# MAX32600 register map
File version: 1.0
Registers are 32-bit, read-write, reset 0x0 unless marked. A register's access mark holds for its fields unless they carry their own. Offsets are from the block's base; [hi:lo] are bit positions; {n}, {i} and the like mark numbered series.

## ADCCFG — ADC
Base 0x40054038
0x00 CTRL1 — ADC Control Register 1
  [18:16] scan_cnt — Channel Scan Count
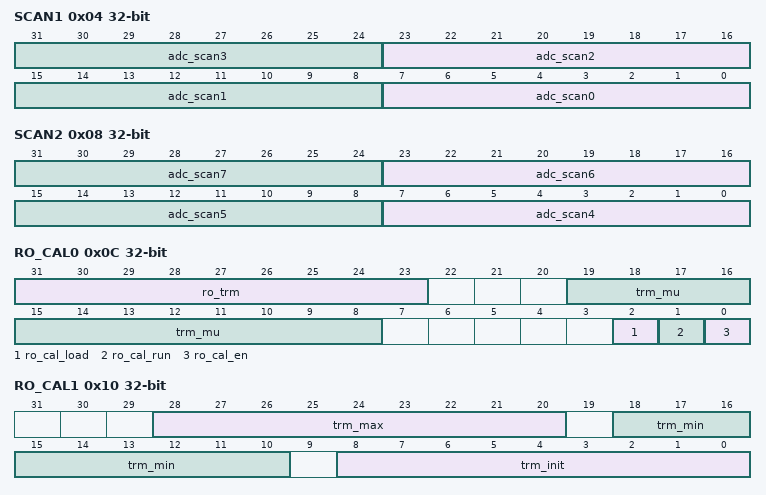
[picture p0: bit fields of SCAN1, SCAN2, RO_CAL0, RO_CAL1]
0x04 SCAN1 — ADC Auto-Scan Settings 1
  [8n+7:8n] adc_scan{n} (n=0..3) — ADC Scan Configuration - Channel {n}
0x08 SCAN2 — ADC Auto-Scan Settings 2
  [8n-25:8n-32] adc_scan{n} (n=4..7) — ADC Scan Configuration - Channel {n}
0x0C RO_CAL0 — ADC Relaxation Oscillator Calibration 0
  [31:23] ro_trm ro — Auto Calibration Loop Register Readback
  [19:8] trm_mu — Auto Calibration Loop Gain
  [2] ro_cal_load — Load Initial RO Calibration Trim
  [1] ro_cal_run — Enable Closed Loop Control
  [0] ro_cal_en — Relaxation Oscillator Auto-Calibration Enable
0x10 RO_CAL1 — ADC Relaxation Oscillator Calibration 1
  [28:20] trm_max — Trim Upper Limit
  [18:10] trm_min — Trim Lower Limit
  [8:0] trm_init — Initial Setting for RO Trim Calibration

## PMU0 — Peripheral Management Unit
Base 0x40070000
Same registers: PMU1 0x40070020, PMU2 0x40070040, PMU3 0x40070060, PMU4 0x40070080, PMU5 0x400700A0
0x00 DSCADR — Starting Descriptor Address
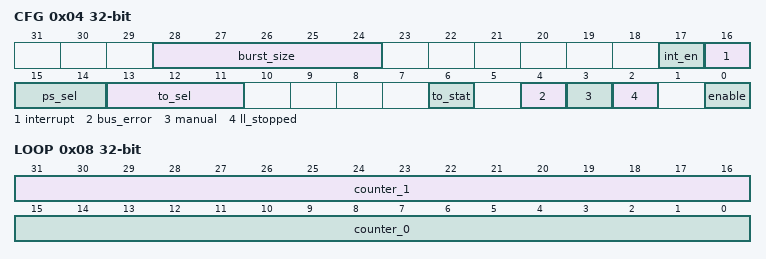
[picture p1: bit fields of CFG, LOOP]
0x04 CFG — Channel Configuration
  [28:24] burst_size — DMA Maximum Burst Size
  [17] int_en — PMU Channel Interrupt Enable
  [16] interrupt write-1-clears — Descriptor Interrupt Flag
  [15:14] ps_sel — Time Out Interval Prescale Select
  [13:11] to_sel — Time Out Interval Select
  [6] to_stat write-1-clears — AHB Bus Timeout Interrupt Flag
  [4] bus_error write-1-clears — AHB Bus Error Interrupt Flag
  [3] manual — Manual Mode Enable
  [2] ll_stopped — Linked List Engine Status
  [0] enable — PMU Channel Enable
0x08 LOOP — Channel Loop Counters
  [31:16] counter_1 — CH1 Loop Counter 0
  [15:0] counter_0 — CH1 Loop Counter 1
0x0C OP — Current Descriptor DWORD 0 (OP)
{0xC+4i} DSC{i} (i=1..4) — Current Descriptor DWORD {i}

## ICC — Instruction Cache
Base 0x40080000
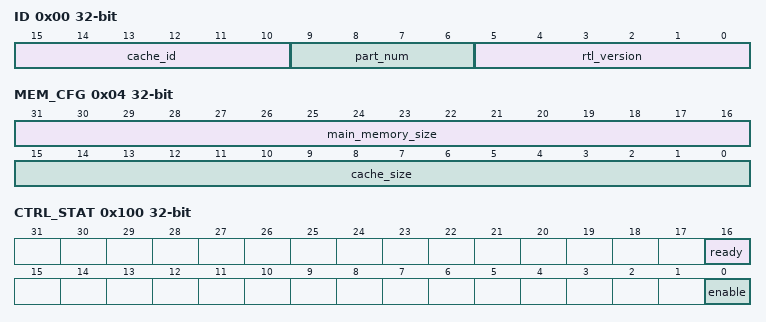
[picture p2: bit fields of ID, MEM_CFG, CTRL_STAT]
0x00 ID — Device ID Register
  [15:10] cache_id ro
  [9:6] part_num ro — Part Number ID
  [5:0] rtl_version ro — RTL Release Version
0x04 MEM_CFG — Memory Configuration
  [31:16] main_memory_size ro, [15:0] cache_size ro
0x100 CTRL_STAT — Control and Status
  [16] ready ro — Cache Ready Status
  [0] enable — Cache Enable
0x700 INVDT_ALL — Invalidate (Clear) Cache Control

## RTCTMR — Real Time Clock
Base 0x40090A00
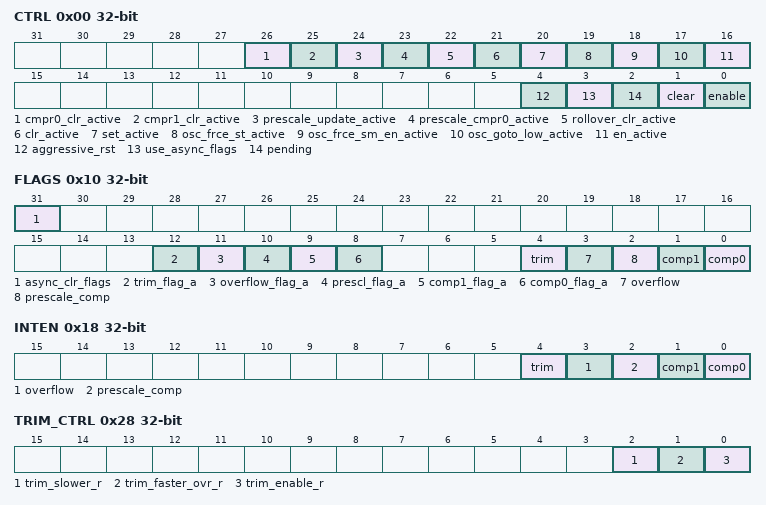
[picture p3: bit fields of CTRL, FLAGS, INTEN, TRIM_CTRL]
0x00 CTRL — RTC Timer Control
  [26] cmpr0_clr_active ro
  [25] cmpr1_clr_active ro
  [24] prescale_update_active ro
  [23] prescale_cmpr0_active ro
  [22] rollover_clr_active ro
  [21] clr_active ro — timer_clr_active
  [20] set_active ro — timer_set_active
  [19] osc_frce_st_active ro
  [18] osc_frce_sm_en_active ro
  [17] osc_goto_low_active ro
  [16] en_active ro — tmr_en_active
  [4] aggressive_rst — Use Aggressive Reset Mode
  [3] use_async_flags — Use Async RTC Flags
  [2] pending ro — RTC Transaction Pending
  [1] clear wo — RTC Timer Clear Bit
  [0] enable — RTC Timer Enable
0x04 TIMER — RTC Timer Count Value
0x08 COMP0 — RTC Time of Day Alarm 0 Compare Register
0x0C COMP1 — RTC Time of Day Alarm 1 Compare Register
0x10 FLAGS — CPU Interrupt and RTC Domain Flags
  [31] async_clr_flags wo — Asynchronous RTC Flag Clear
  [12] trim_flag_a ro — RTC Trim Event 4kHz Flag
  [11] overflow_flag_a ro — RTC Overflow 4kHz Flag
  [10] prescl_flag_a ro — RTC Prescale Compare 4kHz Flag
  [9] comp1_flag_a ro — RTC Compare 1 4kHz Flag
  [8] comp0_flag_a ro — RTC Compare 0 4kHz Flag
  [4] trim write-1-clears — RTC Trim Interrupt Status
  [3] overflow write-1-clears — RTC Overflow Interrupt Status
  [2] prescale_comp write-1-clears — RTC Prescale Compare Int Status
  [1] comp1 write-1-clears — RTC Compare 1 Interrupt Status
  [0] comp0 write-1-clears — RTC Compare 0 Interrupt Status
0x18 INTEN — Interrupt Enable Controls
  [4] trim — RTC Trim Adjust Event Interrupt Enable
  [3] overflow — RTC Overflow Interrupt Enable
  [2] prescale_comp — RTC Prescale Compare Int Enable
  [1] comp1 — RTC Time of Day Alarm (Compare 1) Interrupt Enable
  [0] comp0 — RTC Time of Day Alarm (Compare 0) Interrupt Enable
0x1C PRESCALE — RTC Timer Prescale Setting
  [3:0] width_selection
0x24 PRESCALE_MASK — RTC Timer Prescale Compare Mask
  [3:0] comp_mask
0x28 TRIM_CTRL — RTC Timer Trim Controls
  [2] trim_slower_r ro — RTC Trim Direction Status
  [1] trim_faster_ovr_r — Force RTC Trim to Faster
  [0] trim_enable_r — Enable RTL Trim of RTC Timer
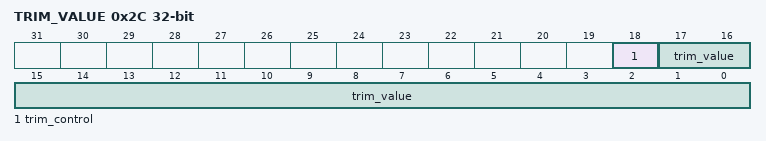
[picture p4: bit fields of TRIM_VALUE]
0x2C TRIM_VALUE — RTC Timer Trim Adjustment Interval
  [18] trim_control — Trim Direction
  [17:0] trim_value — Trim PPM Value

## RTCCFG — Real Time Clock
Base 0x40090A70
0x00 NANO_CNTR — Nano Oscillator Counter Read Register
  [15:0] nanoring_counter ro — Nano Oscillator Counter
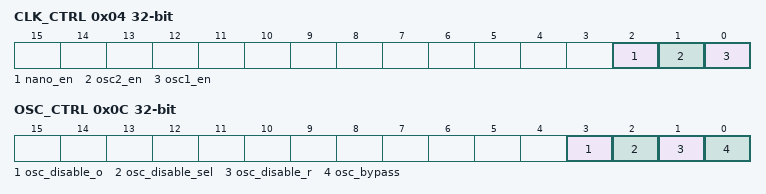
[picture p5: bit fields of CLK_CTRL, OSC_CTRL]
0x04 CLK_CTRL — RTC Clock Control Settings
  [2] nano_en, [1] osc2_en, [0] osc1_en
0x08 DSEN_CTRL — Dynamic Tamper Sensor Control
  [0] dsen_disable — dsen0_dis_o
0x0C OSC_CTRL — RTC Oscillator Control
  [3] osc_disable_o ro, [2] osc_disable_sel, [1] osc_disable_r, [0] osc_bypass

## FLC — Flash Controller
Base 0x400F0000
0x00 FADDR — Flash Operation Address
  [17:0] faddr
0x04 FCKDIV — Flash Clock Pulse Divisor
  [4:0] fckdiv
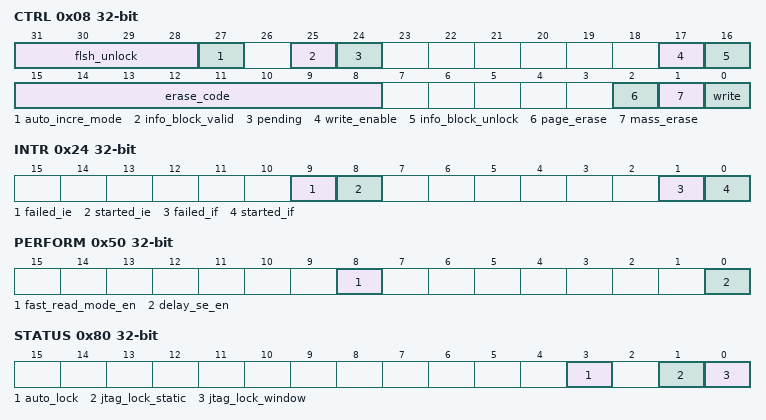
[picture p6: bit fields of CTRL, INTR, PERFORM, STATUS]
0x08 CTRL — Flash Control Register
  [31:28] flsh_unlock — Flash Write/Erase Enable
  [27] auto_incre_mode — Address Auto-Increment Mode
  [25] info_block_valid ro — Info Block Valid Status
  [24] pending ro — Flash Controller Status
  [17] write_enable ro — Flash Writes Enabled
  [16] info_block_unlock ro — Flash Info Block Locked
  [15:8] erase_code — Flash Erase Code
  [2] page_erase — Start Flash Page Erase Operation
  [1] mass_erase — Start Flash Mass Erase Operation
  [0] write — Start Flash Write Operation
0x24 INTR — Flash Controller Interrupt Flags and Enable/Disable 0
  [9] failed_ie — Flash Operation Failed Interrupt Enable
  [8] started_ie — Flash Operation Started Interrupt Enable
  [1] failed_if — Flash Operation Failed
  [0] started_if — Flash Operation Started
0x30 FDATA — Flash Operation Data Register
0x50 PERFORM — Flash Performance Settings
  [8] fast_read_mode_en — Fast Read Mode Enable
  [0] delay_se_en — Delay SE Enable
0x80 STATUS — Security Status Flags
  [3] auto_lock ro — Debug Locked - Auto Lock
  [1] jtag_lock_static ro — Debug Locked - Firmware Lockout
  [0] jtag_lock_window ro — Debug Locked - Hardware Window
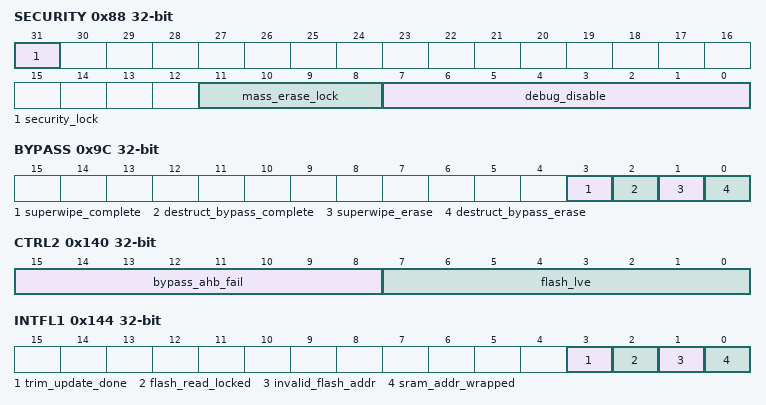
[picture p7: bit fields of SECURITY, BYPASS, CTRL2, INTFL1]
0x88 SECURITY — Flash Controller Security Settings
  [31] security_lock
  [11:8] mass_erase_lock — Mass Erase Lockout
  [7:0] debug_disable — Debug Lockout
0x9C BYPASS — Status Flags for DSB Operations
  [3] superwipe_complete ro — Superwipe Erase Complete
  [2] destruct_bypass_complete ro — Destructive Security Bypass Erase Complete
  [1] superwipe_erase ro — Superwipe Erase In Progress
  [0] destruct_bypass_erase ro — Destructive Security Bypass In Progress
0x100 USER_OPTION — Used to set DSB Access code and Auto-Lock in info block
0x140 CTRL2 — Flash Control Register 2
  [15:8] bypass_ahb_fail — AHB Fail Bypass
  [7:0] flash_lve — Flash LVE Enable
0x144 INTFL1 — Interrupt Flags Register 1
  [3] trim_update_done write-1-clears — Trim Update Complete Interrupt Flag
  [2] flash_read_locked write-1-clears — Flash Read from Locked Area Interrupt Flag
  [1] invalid_flash_addr write-1-clears — Invalid Flash Address Interrupt Flag
  [0] sram_addr_wrapped write-1-clears — SRAM Address Wrapped Interrupt Flag
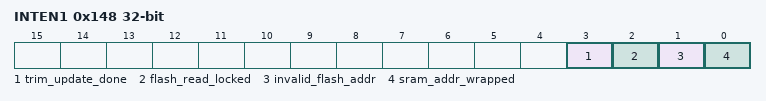
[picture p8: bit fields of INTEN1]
0x148 INTEN1 — Interrupt Enable/Disable Register 1
  [3] trim_update_done write-1-clears — Trim Update Complete Interrupt Enable/Disable
  [2] flash_read_locked write-1-clears — Flash Read from Locked Area Interrupt Enable/Disable
  [1] invalid_flash_addr write-1-clears — Invalid Flash Address Interrupt Enable/Disable
  [0] sram_addr_wrapped write-1-clears — SRAM Address Wrapped Interrupt Enable/Disable
{0x150+4i} DISABLE_XR{i} (i=0..3) — Disable Flash Page Exec/Read Register {i}
{0x160+4i} DISABLE_WE{i} (i=0..3) — Disable Flash Page Write/Erase Register {i}
